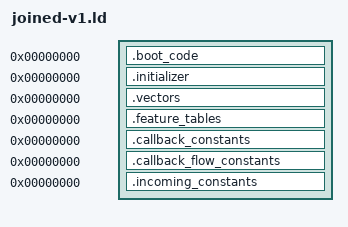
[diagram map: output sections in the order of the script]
OUTPUT_ARCH(riscv)
SECTIONS
{
 .boot_code 0 : SUBALIGN(2) { *(.boot_code)
  *(.text.tsl9_main_runtime_external_9334)
  *(.text.tsl9_main_services_block_9342)
  *(.text.tsl9_main_services_block_934e)
  *(.text.tsl9_main_services_block_9362)
  *(.text.tsl9_main_services_block_9366)
  *(.text.tsl9_main_services_block_936c)
  *(.text.tsl9_main_services_block_9372)
  *(.text.tsl9_main_runtime_external_12506)
  *(.text.tsl9_main_services_block_12528)
  *(.text.tsl9_main_services_block_1253c)
  *(.text.tsl9_main_services_block_12550)
  *(.text.tsl9_main_services_block_12560)
  *(.text.tsl9_main_services_block_1256a)
  *(.text.tsl9_main_services_block_12576)
  *(.text.tsl9_main_services_block_12582)
  *(.text.tsl9_main_services_block_125a8)
  *(.text.tsl9_main_services_block_125b6)
  *(.text.tsl9_main_services_block_125c6)
  *(.text.tsl9_main_services_block_125d6)
  *(.text.tsl9_main_services_block_125e6)
  *(.text.tsl9_main_services_block_12608)
  *(.text.tsl9_main_services_block_1261a)
  *(.text.tsl9_main_services_block_12624)
  *(.text.tsl9_main_services_block_1262e)
  *(.text.tsl9_main_services_block_1263c)
  *(.text.tsl9_main_provider_14c8a)
  *(.text.tsl9_main_services_block_14ca6)
  *(.text.tsl9_main_provider_154a6)
  *(.text.tsl9_main_services_block_154ba)
  *(.text.tsl9_main_services_block_154be)
  *(.text.tsl9_main_services_block_154c2)
  *(.text.tsl9_main_services_block_154c6)
  *(.text.tsl9_main_services_block_154ca)
  *(.text.tsl9_main_services_block_154ce)
  *(.text.tsl9_main_services_block_154d2)
  *(.text.tsl9_main_services_block_154d6)
  *(.text.tsl9_main_services_block_154da)
  *(.text.tsl9_main_services_block_154de)
  *(.text.tsl9_main_services_block_154e2)
  *(.text.tsl9_main_services_block_154e6)
  *(.text.tsl9_main_services_block_154ea)
  *(.text.tsl9_main_services_block_154ee)
  *(.text.tsl9_main_services_block_154f2)
  *(.text.tsl9_main_services_block_154f6)
  *(.text.tsl9_main_services_block_154fa)
  *(.text.tsl9_main_services_block_154fe)
  *(.text.tsl9_main_services_block_15502)
  *(.text.tsl9_main_services_block_15506)
  *(.text.tsl9_main_services_block_1550a)
  *(.text.tsl9_main_services_block_1550e)
  *(.text.tsl9_main_services_block_15512)
  *(.text.tsl9_main_services_block_15516)
  *(.text.tsl9_main_services_block_1551a)
  *(.text.tsl9_main_services_block_1551e)
  *(.text.tsl9_main_services_block_15522)
  *(.text.tsl9_main_provider_17040)
  *(.text.tsl9_main_services_block_1705a)
  *(.text.tsl9_main_services_block_1706c)
  *(.text.tsl9_main_services_block_17082)
  *(.text.tsl9_main_services_block_170e8)
  *(.text.tsl9_main_services_block_170f8)
  *(.text.tsl9_main_services_block_17108)
  *(.text.tsl9_main_services_block_17116)
  *(.text.tsl9_main_services_block_1712e)
  *(.text.tsl9_main_services_block_1713c)
  *(.text.tsl9_main_services_block_17146)
  *(.text.tsl9_main_services_block_17152)
  *(.text.tsl9_main_services_block_17160)
  *(.text.tsl9_main_services_block_1716c)
  *(.text.tsl9_main_services_block_1719a)
  *(.text.tsl9_main_services_block_171a4)
  *(.text.tsl9_main_services_block_171ae)
 }
 .initializer 0 : SUBALIGN(4) { *(.initializer) }
 .vectors 0 : SUBALIGN(4) { *(.vectors) }
 .feature_tables 0 : SUBALIGN(4) { *(.feature_tables) }
 .callback_constants 0 : SUBALIGN(4) { *(.callback_constants) }
 .callback_flow_constants 0 : SUBALIGN(4) { *(.callback_flow_constants) }
 .incoming_constants 0 : SUBALIGN(4) { *(.incoming_constants) }
 /DISCARD/ : { *(.comment) *(.riscv.attributes) *(.llvm_addrsig) }
}
